# AT90USB1286 register map
Vendor: Atmel; File version: 1.0
CPU: other r0p0, little endian, no MPU, no FPU, 4 interrupt priority bits
Registers are 8-bit, read-write, reset 0x0 unless marked. A register's access mark holds for its fields unless they carry their own. Offsets are from the block's base; [hi:lo] are bit positions.

## TC2 — Timer/Counter, 8-bit Async
Base 0x00800037
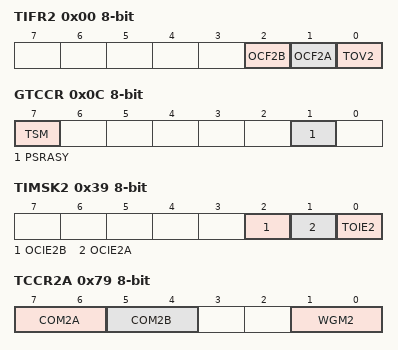
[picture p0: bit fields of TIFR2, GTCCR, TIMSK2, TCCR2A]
0x00 TIFR2 — Timer/Counter Interrupt Flag Register (read-only for debugger)
  [2] OCF2B — Output Compare Flag 2B
  [1] OCF2A — Output Compare Flag 2A
  [0] TOV2 — Timer/Counter2 Overflow Flag
0x0C GTCCR — General Timer Counter Control register
  [7] TSM — Timer/Counter Synchronization Mode
  [1] PSRASY — Prescaler Reset Timer/Counter2
0x39 TIMSK2 — Timer/Counter Interrupt Mask register
  [2] OCIE2B — Timer/Counter2 Output Compare Match B Interrupt Enable
  [1] OCIE2A — Timer/Counter2 Output Compare Match A Interrupt Enable
  [0] TOIE2 — Timer/Counter2 Overflow Interrupt Enable
0x79 TCCR2A — Timer/Counter2 Control Register A
  [7:6] COM2A — Compare Output Mode bits
  [5:4] COM2B — Compare Output Mode bits
  [1:0] WGM2 — Waveform Generation Mode
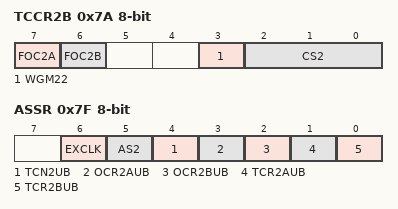
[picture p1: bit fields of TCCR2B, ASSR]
0x7A TCCR2B — Timer/Counter2 Control Register B
  [7] FOC2A — Force Output Compare A
  [6] FOC2B — Force Output Compare B
  [3] WGM22 — Waveform Generation Mode
  [2:0] CS2 — Clock Select bits
    0=NO_CLOCK_SOURCE_STOPPED; 1=RUNNING_NO_PRESCALING; 2=RUNNING_CLK_8; 3=RUNNING_CLK_32; 4=RUNNING_CLK_64; 5=RUNNING_CLK_128; 6=RUNNING_CLK_256; 7=RUNNING_CLK_1024
0x7B TCNT2 — Timer/Counter2
0x7C OCR2A — Timer/Counter2 Output Compare Register A
0x7D OCR2B — Timer/Counter2 Output Compare Register B
0x7F ASSR — Asynchronous Status Register
  [6] EXCLK — Enable External Clock Input
  [5] AS2 — Asynchronous Timer/Counter2
  [4] TCN2UB — Timer/Counter2 Update Busy
  [3] OCR2AUB — Output Compare Register2 Update Busy
  [2] OCR2BUB — Output Compare Register 2 Update Busy
  [1] TCR2AUB — Timer/Counter Control Register2 Update Busy
  [0] TCR2BUB — Timer/Counter Control Register2 Update Busy

## TC3 — Timer/Counter, 16-bit
Base 0x00800038
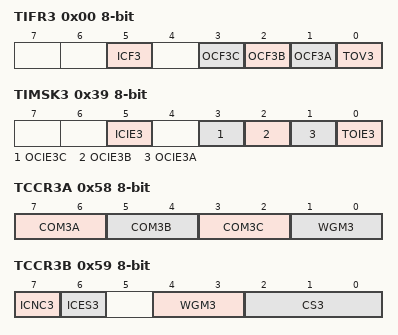
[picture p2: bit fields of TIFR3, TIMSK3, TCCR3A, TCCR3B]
0x00 TIFR3 — Timer/Counter3 Interrupt Flag register (read-only for debugger)
  [5] ICF3 — Input Capture Flag 3
  [3] OCF3C — Output Compare Flag 3C
  [2] OCF3B — Output Compare Flag 3B
  [1] OCF3A — Output Compare Flag 3A
  [0] TOV3 — Timer/Counter3 Overflow Flag
0x39 TIMSK3 — Timer/Counter3 Interrupt Mask Register
  [5] ICIE3 — Timer/Counter3 Input Capture Interrupt Enable
  [3] OCIE3C — Timer/Counter3 Output Compare C Match Interrupt Enable
  [2] OCIE3B — Timer/Counter3 Output Compare B Match Interrupt Enable
  [1] OCIE3A — Timer/Counter3 Output Compare A Match Interrupt Enable
  [0] TOIE3 — Timer/Counter3 Overflow Interrupt Enable
0x58 TCCR3A — Timer/Counter3 Control Register A
  [7:6] COM3A — Compare Output Mode 1A, bits
  [5:4] COM3B — Compare Output Mode 3B, bits
  [3:2] COM3C — Compare Output Mode 3C, bits
  [1:0] WGM3 — Waveform Generation Mode
0x59 TCCR3B — Timer/Counter3 Control Register B
  [7] ICNC3 — Input Capture 3 Noise Canceler
  [6] ICES3 — Input Capture 3 Edge Select
  [4:3] WGM3 — Waveform Generation Mode
  [2:0] CS3 — Prescaler source of Timer/Counter 3
    0=NO_CLOCK_SOURCE_STOPPED; 1=RUNNING_NO_PRESCALING; 2=RUNNING_CLK_8; 3=RUNNING_CLK_64; 4=RUNNING_CLK_256; 5=RUNNING_CLK_1024; 6=RUNNING_EXTCLK_TN_FALLING_EDGE; 7=RUNNING_EXTCLK_TN_RISING_EDGE
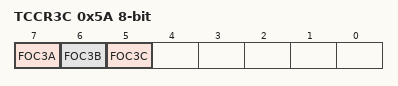
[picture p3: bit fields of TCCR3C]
0x5A TCCR3C — Timer/Counter 3 Control Register C
  [7] FOC3A — Force Output Compare 3A
  [6] FOC3B — Force Output Compare 3B
  [5] FOC3C — Force Output Compare 3C
0x5C TCNT3 16-bit (reset mask 0xFF) — Timer/Counter3 Bytes
0x5E ICR3 16-bit (reset mask 0xFF) — Timer/Counter3 Input Capture Register Bytes
0x60 OCR3A 16-bit (reset mask 0xFF) — Timer/Counter3 Output Compare Register A Bytes
0x62 OCR3B 16-bit (reset mask 0xFF) — Timer/Counter3 Output Compare Register B Bytes
0x64 OCR3C 16-bit (reset mask 0xFF) — Timer/Counter3 Output Compare Register B Bytes

## TWI — Two Wire Serial Interface
Base 0x008000B8
0x00 TWBR — TWI Bit Rate register
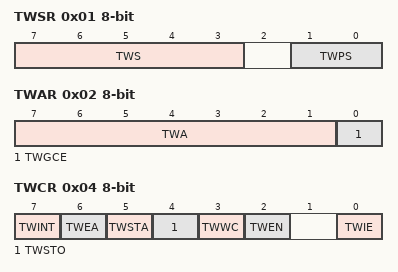
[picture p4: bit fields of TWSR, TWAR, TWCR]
0x01 TWSR — TWI Status Register
  [7:3] TWS — TWI Status
  [1:0] TWPS — TWI Prescaler
    0=1; 1=4; 2=16; 3=64
0x02 TWAR — TWI (Slave) Address register
  [7:1] TWA — TWI (Slave) Address register Bits
  [0] TWGCE — TWI General Call Recognition Enable Bit
0x03 TWDR — TWI Data register
0x04 TWCR — TWI Control Register (read-only for debugger)
  [7] TWINT — TWI Interrupt Flag
  [6] TWEA — TWI Enable Acknowledge Bit
  [5] TWSTA — TWI Start Condition Bit
  [4] TWSTO — TWI Stop Condition Bit
  [3] TWWC — TWI Write Collision Flag
  [2] TWEN — TWI Enable Bit
  [0] TWIE — TWI Interrupt Enable
0x05 TWAMR — TWI (Slave) Address Mask Register
  [7:1] TWAM

## USART1 — USART
Base 0x008000C8
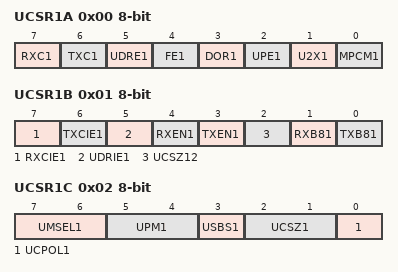
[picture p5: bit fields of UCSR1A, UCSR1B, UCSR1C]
0x00 UCSR1A — USART Control and Status Register A (read-only for debugger)
  [7] RXC1 — USART Receive Complete
  [6] TXC1 — USART Transmit Complete
  [5] UDRE1 — USART Data Register Empty
  [4] FE1 — Framing Error
  [3] DOR1 — Data overRun
  [2] UPE1 — Parity Error
  [1] U2X1 — Double the USART transmission speed
  [0] MPCM1 — Multi-processor Communication Mode
0x01 UCSR1B — USART Control and Status Register B
  [7] RXCIE1 — RX Complete Interrupt Enable
  [6] TXCIE1 — TX Complete Interrupt Enable
  [5] UDRIE1 — USART Data register Empty Interrupt Enable
  [4] RXEN1 — Receiver Enable
  [3] TXEN1 — Transmitter Enable
  [2] UCSZ12 — Character Size
  [1] RXB81 — Receive Data Bit 8
  [0] TXB81 — Transmit Data Bit 8
0x02 UCSR1C — USART Control and Status Register C
  [7:6] UMSEL1 — USART Mode Select
    0=ASYNCHRONOUS_USART; 1=SYNCHRONOUS_USART; 3=MASTER_SPI
  [5:4] UPM1 — Parity Mode Bits
    0=DISABLED; 2=ENABLED_EVEN_PARITY; 3=ENABLED_ODD_PARITY
  [3] USBS1 — Stop Bit Select
    0=1_BIT; 1=2_BIT
  [2:1] UCSZ1 — Character Size
  [0] UCPOL1 — Clock Polarity
0x04 UBRR1 16-bit (reset mask 0xFF) — USART Baud Rate Register Bytes
0x06 UDR1 — USART I/O Data Register (write-only for debugger)

## USB_DEVICE — USB Device Registers
Base 0x008000E0
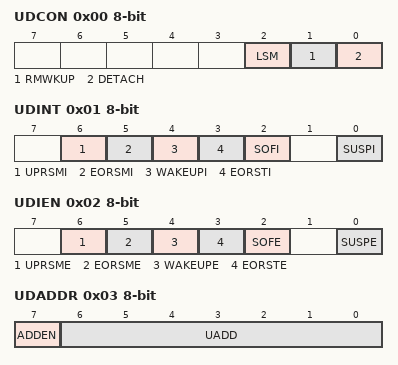
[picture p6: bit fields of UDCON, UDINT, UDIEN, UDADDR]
0x00 UDCON
  [2] LSM, [1] RMWKUP, [0] DETACH
0x01 UDINT
  [6] UPRSMI, [5] EORSMI, [4] WAKEUPI, [3] EORSTI, [2] SOFI, [0] SUSPI
0x02 UDIEN
  [6] UPRSME, [5] EORSME, [4] WAKEUPE, [3] EORSTE, [2] SOFE, [0] SUSPE
0x03 UDADDR
  [7] ADDEN, [6:0] UADD
0x04 UDFNUM 16-bit (reset mask 0xFF)
0x06 UDMFN
  [4] FNCERR
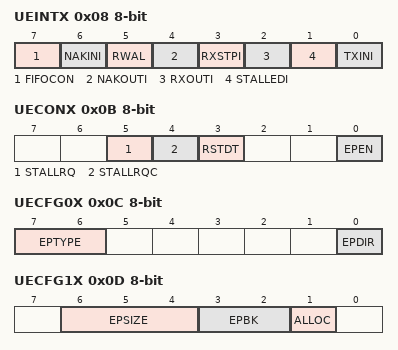
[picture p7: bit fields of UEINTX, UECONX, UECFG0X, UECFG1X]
0x08 UEINTX
  [7] FIFOCON, [6] NAKINI, [5] RWAL, [4] NAKOUTI, [3] RXSTPI, [2] RXOUTI, [1] STALLEDI, [0] TXINI
0x09 UENUM
0x0A UERST
  [6:0] EPRST
0x0B UECONX
  [5] STALLRQ, [4] STALLRQC, [3] RSTDT, [0] EPEN
0x0C UECFG0X
  [7:6] EPTYPE, [0] EPDIR
0x0D UECFG1X
  [6:4] EPSIZE, [3:2] EPBK, [1] ALLOC
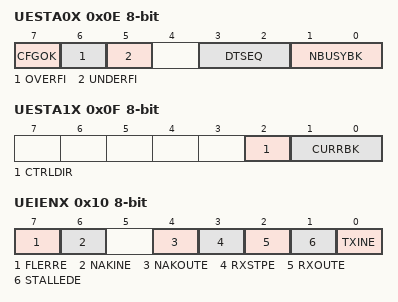
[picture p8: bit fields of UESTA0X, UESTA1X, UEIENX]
0x0E UESTA0X
  [7] CFGOK, [6] OVERFI, [5] UNDERFI, [3:2] DTSEQ, [1:0] NBUSYBK
0x0F UESTA1X
  [2] CTRLDIR, [1:0] CURRBK
0x10 UEIENX
  [7] FLERRE, [6] NAKINE, [4] NAKOUTE, [3] RXSTPE, [2] RXOUTE, [1] STALLEDE, [0] TXINE
0x11 UEDATX
0x12 UEBCLX
0x13 UEBCHX
0x14 UEINT

## USB_GLOBAL — USB Controller
Base 0x008000D7
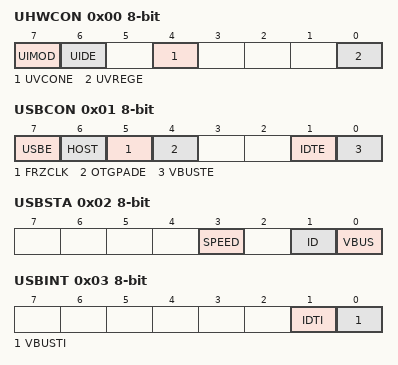
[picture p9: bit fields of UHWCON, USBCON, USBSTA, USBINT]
0x00 UHWCON — USB Hardware Configuration Register
  [7] UIMOD, [6] UIDE, [4] UVCONE, [0] UVREGE
0x01 USBCON — USB General Control Register
  [7] USBE, [6] HOST, [5] FRZCLK, [4] OTGPADE, [1] IDTE, [0] VBUSTE
0x02 USBSTA
  [3] SPEED, [1] ID, [0] VBUS
0x03 USBINT
  [1] IDTI, [0] VBUSTI

## WDT — Watchdog Timer
Base 0x00800060
0x00 WDTCSR — Watchdog Timer Control Register (read-only for debugger)
  [7] WDIF — Watchdog Timeout Interrupt Flag
  [6] WDIE — Watchdog Timeout Interrupt Enable
  [4] WDCE — Watchdog Change Enable
  [3] WDE — Watch Dog Enable
  [5:0] WDP — Watchdog Timer Prescaler Bits
    0=OSCILLATOR_CYCLES_2K; 1=OSCILLATOR_CYCLES_4K; 2=OSCILLATOR_CYCLES_8K; 3=OSCILLATOR_CYCLES_16K; 4=OSCILLATOR_CYCLES_32K; 5=OSCILLATOR_CYCLES_64K; 6=OSCILLATOR_CYCLES_128K; 7=OSCILLATOR_CYCLES_256K
